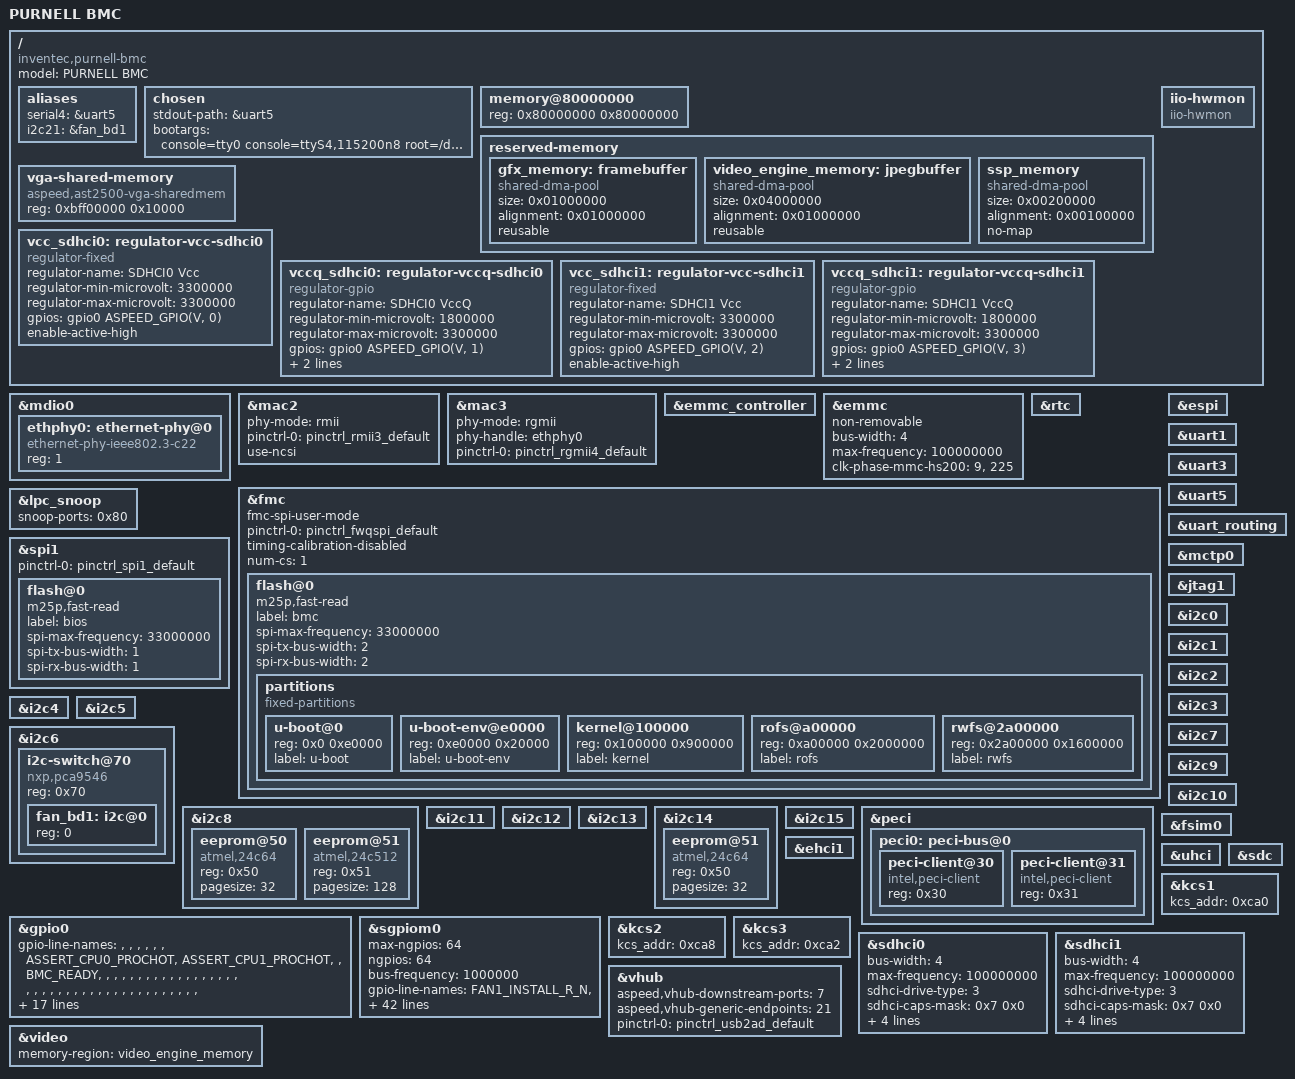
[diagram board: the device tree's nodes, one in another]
// SPDX-License-Identifier: GPL-2.0-or-later
// Copyright 2019 IBM Corp.

/dts-v1/;

#include "aspeed-g6.dtsi"
#include "aspeed-g6-pinctrl.dtsi"
#include <dt-bindings/i2c/i2c.h>
#include <dt-bindings/gpio/aspeed-gpio.h>

/ {
	model = "PURNELL BMC";
	compatible = "inventec,purnell-bmc", "aspeed,ast2600";

	aliases {
		serial4 = &uart5;
                i2c21 = &fan_bd1;
	};

	chosen {
		stdout-path = &uart5;
		bootargs = "console=tty0 console=ttyS4,115200n8 root=/dev/ram rw init=/linuxrc";
	};

	memory@80000000 {
		device_type = "memory";
		reg = <0x80000000 0x80000000>;
	};

	reserved-memory {
		#address-cells = <1>;
		#size-cells = <1>;
		ranges;

		gfx_memory: framebuffer {
			size = <0x01000000>;
			alignment = <0x01000000>;
			compatible = "shared-dma-pool";
			reusable;
		};

		video_engine_memory: jpegbuffer {
			size = <0x04000000>; /*64MB*/
			alignment = <0x01000000>;
			compatible = "shared-dma-pool";
			reusable;
		};

		ssp_memory: ssp_memory {
			size = <0x00200000>;
			alignment = <0x00100000>;
			compatible = "shared-dma-pool";
			no-map;
		};
#if 0
		espi_peripheral_memory: espi_peripheral_memory {
			no-map;
			reg = <0x98000000 0x04000000>; /* 64M */
			size = <0x01000000>;
			alignment = <0x01000000>;
			compatible = "shared-dma-pool";
			reusable;
		};
#endif
};

	vga-shared-memory {
		compatible = "aspeed,ast2500-vga-sharedmem";
		reg = <0xbff00000 0x10000>;
	};

	iio-hwmon {
		compatible = "iio-hwmon";
#if 0 //Because in this commit "7ce44bd7 [purnell][sync ca35761][superion][bringup][dbus] add dbus sensors
      //we have already added it, but at the Power On stage, we temporarily remove all I2C devices.
		io-channels =
			<&adc_u74 0>, // AIN0
			<&adc_u74 1>, // AIN1
			<&adc_u74 2>, // P0_3V3_S5
			<&adc_u74 3>, // P1_3V3_S5
			<&adc_u74 4>, // P3V3
			<&adc_u74 5>, // VBAT
			<&adc_u74 6>, // P3V3_AUX
			<&adc_u74 7>, // P5V_AUX
			<&adc_u74 8>, // P5V
			<&adc_u74 9>, // P12V
			<&adc_u74 10>, // P1V8_AUX
			<&adc_u74 11> // P1V05_AUX
			;
#endif
    };

	vcc_sdhci0: regulator-vcc-sdhci0 {
		compatible = "regulator-fixed";
		regulator-name = "SDHCI0 Vcc";
		regulator-min-microvolt = <3300000>;
		regulator-max-microvolt = <3300000>;
		gpios = <&gpio0 ASPEED_GPIO(V, 0) GPIO_ACTIVE_HIGH>;
		enable-active-high;
	};

	vccq_sdhci0: regulator-vccq-sdhci0 {
		compatible = "regulator-gpio";
		regulator-name = "SDHCI0 VccQ";
		regulator-min-microvolt = <1800000>;
		regulator-max-microvolt = <3300000>;
		gpios = <&gpio0 ASPEED_GPIO(V, 1) GPIO_ACTIVE_HIGH>;
		gpios-states = <1>;
		states = <3300000 1>,
			 <1800000 0>;
	};

	vcc_sdhci1: regulator-vcc-sdhci1 {
		compatible = "regulator-fixed";
		regulator-name = "SDHCI1 Vcc";
		regulator-min-microvolt = <3300000>;
		regulator-max-microvolt = <3300000>;
		gpios = <&gpio0 ASPEED_GPIO(V, 2) GPIO_ACTIVE_HIGH>;
		enable-active-high;
	};

	vccq_sdhci1: regulator-vccq-sdhci1 {
		compatible = "regulator-gpio";
		regulator-name = "SDHCI1 VccQ";
		regulator-min-microvolt = <1800000>;
		regulator-max-microvolt = <3300000>;
		gpios = <&gpio0 ASPEED_GPIO(V, 3) GPIO_ACTIVE_HIGH>;
		gpios-states = <1>;
		states = <3300000 1>,
			 <1800000 0>;
	};
};

&mdio0 {
	status = "okay";

	ethphy0: ethernet-phy@0 {
		compatible = "ethernet-phy-ieee802.3-c22";
		reg = <1>;
	};
};

&mac2 {
        status = "okay";
        pinctrl-names = "default";
        phy-mode = "rmii";
        pinctrl-0 = <&pinctrl_rmii3_default>;
        use-ncsi;
};

&mac3 {
	status = "okay";

	phy-mode = "rgmii";
	phy-handle = <&ethphy0>;

	pinctrl-names = "default";
	pinctrl-0 = <&pinctrl_rgmii4_default>;
};

&emmc_controller {
	status = "okay";
};

&emmc {
	non-removable;
	bus-width = <4>;
	max-frequency = <100000000>;
	clk-phase-mmc-hs200 = <9>, <225>;
};

&rtc {
	status = "okay";
};

&fmc {
	fmc-spi-user-mode;
	pinctrl-names = "default";
	pinctrl-0 = <&pinctrl_fwqspi_default>;
	timing-calibration-disabled;
	status = "okay";
	num-cs = <1>;
	flash@0 {
		status = "okay";
		m25p,fast-read;
		label = "bmc";
		spi-max-frequency = <33000000>;
		spi-tx-bus-width = <2>;
		spi-rx-bus-width = <2>;
		partitions {
			compatible = "fixed-partitions";
			#address-cells = <0x1>;
			#size-cells = <0x1>;

			u-boot@0 {
				reg = <0x0 0xe0000>;
				label = "u-boot";
			};

			u-boot-env@e0000 {
				reg = <0xe0000 0x20000>;
				label = "u-boot-env";
			};

			kernel@100000 {
				reg = <0x100000 0x900000>;
				label = "kernel";
			};

			rofs@a00000 {
				reg = <0xa00000 0x2000000>;
				label = "rofs";
			};

			rwfs@2a00000 {
				reg = <0x2a00000 0x1600000>;
				label = "rwfs";
			};
		};
	};
};

&lpc_snoop {
	status = "okay";
	snoop-ports = <0x80>;
};

&espi {
        status = "okay";
};

&spi1 {
	status = "okay";
	pinctrl-names = "default";
	pinctrl-0 = <&pinctrl_spi1_default>;
	flash@0 {
		status = "okay";
		m25p,fast-read;
		label = "bios";
		spi-max-frequency = <33000000>;
		spi-tx-bus-width = <1>;
		spi-rx-bus-width = <1>;
	};
};

&uart1 {
        status = "okay";
};

&uart3 {
        status = "okay";
};

&uart5 {
	status = "okay";
};

&uart_routing {
	status = "okay";
};

&mctp0 {
	status = "okay";
};

&jtag1 {
	status = "okay";
};

&i2c0 {
	status = "okay";
};

&i2c1 {
	status = "okay";
};

&i2c2 {
	status = "okay";
};

&i2c3 {
	status = "okay";
};

&i2c4 {
	status = "okay";
};

&i2c5 {
	status = "okay";
};	

&i2c6 {
	status = "okay";
        i2c-switch@70 {
                compatible = "nxp,pca9546";
                #address-cells = <1>;
                #size-cells = <0>;
                reg = <0x70>;

                /* 12c-16 */
                fan_bd1: i2c@0 {
                        #address-cells = <1>;
                        #size-cells = <0>;
                        reg = <0>;
                };
        };

};

&i2c7 {
	status = "okay";
};

&i2c8 {
	status = "okay";

	/* SCM EEPROM*/
	eeprom@50 {
		compatible = "atmel,24c64";
		reg = <0x50>;
		pagesize = <32>;
	};

	/* RunBMC EEPROM*/
	eeprom@51 {
		compatible = "atmel,24c512";
		reg = <0x51>;
		pagesize = <128>;
	};
};

&i2c9 {
	status = "okay";
};

&i2c10 {
	status = "okay";
};

&i2c11 {
	status = "okay";
};

&i2c12 {
	status = "okay";
};

&i2c13 {
        status = "okay";
};

&i2c14 {
        status = "okay";

        /* PURNELL DCSCM_EEPROM*/
        eeprom@51 {
            compatible = "atmel,24c64";
            reg = <0x50>;
            pagesize = <32>;
            };
};

&i2c15 {
	status = "okay";
};

&peci{
	peci0: peci-bus@0{
		status = "okay";

		peci-client@30 {
			compatible = "intel,peci-client";
			reg = <0x30>;
		};

		peci-client@31 {
			compatible = "intel,peci-client";
			reg = <0x31>;
		};
	};
};

&gpio0 {
	status = "okay";
	gpio-line-names =
	/*A0-A7*/   "","","","","","","ASSERT_CPU0_PROCHOT","ASSERT_CPU1_PROCHOT",
	/*B0-B7*/   "","BMC_READY","","","","","","",
	/*C0-C7*/   "","","","","","","","",
	/*D0-D7*/   "","","","","","","","",
	/*E0-E7*/   "","","","","","","","",
	/*F0-F7*/   "","","","","","","","",
	/*G0-G7*/   "","","","","","","","",
	/*H0-H7*/   "","","","","RST_BTN_BMC_OUT","","","",
	/*I0-I7*/   "","","","","","","BMC_PWR_BTN_OUT","",
	/*J0-J7*/   "","","","","","","","",
	/*K0-K7*/   "","","","","","","","",
	/*L0-L7*/   "","","","","","","","",
	/*M0-M7*/   "","","","DBP_HOOK3_CPU_FBRK_OUT","PREQ_N","PRDY_N","","",
	/*N0-N7*/   "","","","","","FM_SPD_SWITCH_CTRL","","",
	/*O0-O7*/   "","","IRQ_BMC_CPU0_NMI_OUT","","IRQ_BMC_CPU1_NMI_OUT","","I3C_SPDMUX_SELECT1","",
	/*P0-P7*/   "","","CPU1_BMCINIT","","","","","",
	/*Q0-Q7*/   "","","","","","","PSU0_PRESENT","",
	/*R0-R7*/   "PSU1_PRESENT","NCSI_OCP_CLK_EN","","NCSI_BMC_CLK_EN","I3C_SPDMUX_SELECT0","","","",
	/*S0-S7*/   "","","BMC_WAKE","","","","","",
	/*T0-T7*/   "","","","","","","","",
	/*U0-U7*/   "","","","","","","","",
	/*V0-V7*/   "RST_BMC_SGPIO","","","","","","","",
	/*W0-W7*/   "","","","","","","","",
	/*X0-X7*/   "","","","","","","","CPU0_BMCINIT",
	/*Y0-Y7*/   "","","","","","","","CPLD_PWRBRK",
	/*Z0-Z7*/   "","RST_CPU0_RTCRST_PLD","","","","","","",
	/*AA0-AA7*/ "","","","","","","","",
	/*AB0-AB7*/ "","","","","","","","",
	/*AC0-AC7*/ "","","","","","","","";
};

&sgpiom0 {
	status = "okay";
	max-ngpios = <64>;
	ngpios = <64>;
	bus-frequency = <1000000>;
	gpio-line-names =
	/*in - out - in - out */
	/*A0-A7*/   "FAN1_INSTALL_R_N","LED_PORT80_0_N","MLB_BRD_REV_ID1","LED_PORT80_1_N","MLB_BRD_REV_ID0","LED_PORT80_2_N","MLB_BRD_SKU_ID3","LED_PORT80_3_N",
	/*A0-A7*/   "MLB_BRD_SKU_ID2","LED_PORT80_4_N","MLB_BRD_SKU_ID1","LED_PORT80_5_N","MLB_BRD_SKU_ID0","LED_PORT80_6_N","FM_TPM_PRSNT_N","LED_PORT80_7_N",
	/*B0-B7*/   "PE_M2_ALERT_R_N","CPLD_JTAG_OE_R_N","PASSWORD_CLEAR_N","RST_PE_SLOT_I2C_MUX_N","IRQ_PSYS_CRIT_N","","FAN6_INSTALL_R_N","",
	/*B0-B7*/   "FAN5_INSTALL_R_N","","FAN4_INSTALL_R_N","","FAN3_INSTALL_R_N","","FAN2_INSTALL_R_N","",
	/*C0-C7*/   "RISER4_ID2_R","","RISER4_ID1_R","","RISER4_ID0_R","","RISER5_ID2_R","",
	/*C0-C7*/   "RISER5_ID1_R","","RISER5_ID0_R","","","","","",
	/*D0-D7*/   "RISER1_ID1_R","","RISER1_ID0_R","","RISER2_ID2_R","","RISER2_ID1_R","",
	/*D0-D7*/   "RISER2_ID0_R","","RISER3_ID2_R","","RISER3_ID1_R","","RISER3_ID0_R","",
	/*E0-E7*/   "PRSNT_RISER3_SLOT1_N","","PRSNT_RISER4_SLOT3_N","","PRSNT_RISER4_SLOT2_N","","PRSNT_RISER4_SLOT1_N","",
	/*E0-E7*/   "PRSNT_RISER5_SLOT3_N","","PRSNT_RISER5_SLOT2_N","","PRSNT_RISER5_SLOT1_N","","RISER1_ID2_R","",
	/*F0-F7*/   "PRSNT_RISER1_SLOT3_N","","PRSNT_RISER1_SLOT2_N","","PRSNT_RISER1_SLOT1_N","","PRSNT_RISER2_SLOT3_N","",
	/*F0-F7*/   "PRSNT_RISER2_SLOT2_N","","PRSNT_RISER2_SLOT1_N","","PRSNT_RISER3_SLOT3_N","","PRSNT_RISER3_SLOT2_N","",
	/*G0-G7*/   "CPU1_CD_INIT_ERROR","","PWRGD_CPU0_S0_PWROK_R","","PWRGD_CPU1_S0_PWROK_R","","RISER1_PRSNT_N_R","",
	/*G0-G7*/   "RISER2_PRSNT_N_R","","RISER3_PRSNT_N_R","","RISER4_PRSNT_N_R","","RISER5_PRSNT_N_R","",
	/*H0-H7*/   "CPU0_PRSNT_N","","CPU1_PRSNT_N","","CPU0_PWR_GOOD","","CPU1_PWR_GOOD","",
	/*H0-H7*/   "PGD_SYS_PWROK","","","","","","CPU0_CD_INIT_ERROR","";
};

&fsim0 {
	status = "okay";
};

&ehci1 {
	status = "okay";
};

&uhci {
	status = "okay";
};

&sdc {
	status = "okay";
};

&kcs1 {
        kcs_addr = <0xca0>;
        status = "okay";
};

&kcs2 {
        kcs_addr = <0xca8>;
        status = "okay";
};

&kcs3 {
        kcs_addr = <0xca2>;
        status = "okay";
};

/*
 * The signal voltage of sdhci0 and sdhci1 on AST2600-A2 EVB is able to be
 * toggled by GPIO pins.
 * In the reference design, GPIOV0 of AST2600-A2 EVB is connected to the
 * power load switch that provides 3.3v to sdhci0 vdd, GPIOV1 is connected to
 * a 1.8v and a 3.3v power load switch that provides signal voltage to
 * sdhci0 bus.
 * If GPIOV0 is active high, sdhci0 is enabled, otherwise, sdhci0 is disabled.
 * If GPIOV1 is active high, 3.3v power load switch is enabled, sdhci0 signal
 * voltage is 3.3v, otherwise, 1.8v power load switch will be enabled,
 * sdhci0 signal voltage becomes 1.8v.
 * AST2600-A2 EVB also supports toggling signal voltage for sdhci1.
 * The design is the same as sdhci0, it uses GPIOV2 as power-gpio and GPIOV3
 * as power-switch-gpio.
 */
&sdhci0 {
	status = "okay";
	bus-width = <4>;
	max-frequency = <100000000>;
	sdhci-drive-type = /bits/ 8 <3>;
	sdhci-caps-mask = <0x7 0x0>;
	sdhci,wp-inverted;
	vmmc-supply = <&vcc_sdhci0>;
	vqmmc-supply = <&vccq_sdhci0>;
	clk-phase-sd-hs = <7>, <200>;
};

&sdhci1 {
	status = "okay";
	bus-width = <4>;
	max-frequency = <100000000>;
	sdhci-drive-type = /bits/ 8 <3>;
	sdhci-caps-mask = <0x7 0x0>;
	sdhci,wp-inverted;
	vmmc-supply = <&vcc_sdhci1>;
	vqmmc-supply = <&vccq_sdhci1>;
	clk-phase-sd-hs = <7>, <200>;
};

&video {
	status = "okay";
	memory-region = <&video_engine_memory>;
};

&vhub {
	status = "okay";
	aspeed,vhub-downstream-ports = <7>;
	aspeed,vhub-generic-endpoints = <21>;
	pinctrl-names = "default";
	pinctrl-0 = <&pinctrl_usb2ad_default>;
};
